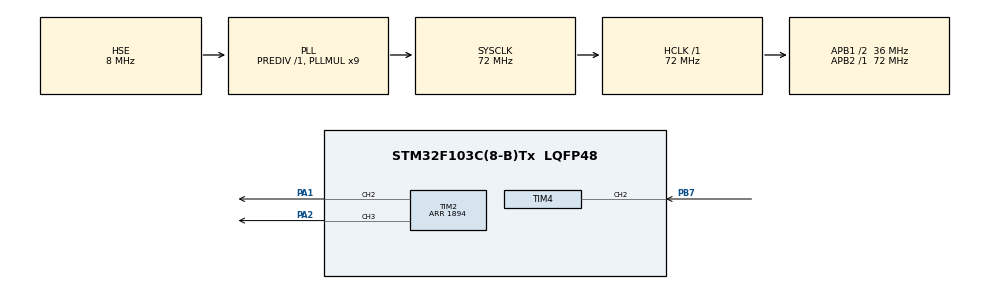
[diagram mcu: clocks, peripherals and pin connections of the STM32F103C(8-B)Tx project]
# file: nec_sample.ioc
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Mcu.Family=STM32F1
Mcu.Name=STM32F103C(8-B)Tx
Mcu.Package=LQFP48
NVIC.PriorityGroup=NVIC_PRIORITYGROUP_4
NVIC.TIM3_IRQn=true\:0\:0\:false\:false\:true\:true\:true\:true
NVIC.TIM4_IRQn=true\:0\:0\:false\:false\:true\:true\:true\:true
PA1.Signal=S_TIM2_CH2
PA13.Mode=Serial_Wire
PA13.Signal=SYS_JTMS-SWDIO
PA14.Mode=Serial_Wire
PA14.Signal=SYS_JTCK-SWCLK
PA2.Signal=S_TIM2_CH3
PB7.Signal=S_TIM4_CH2
PD0-OSC_IN.Mode=HSE-External-Oscillator
PD0-OSC_IN.Signal=RCC_OSC_IN
PD1-OSC_OUT.Mode=HSE-External-Oscillator
PD1-OSC_OUT.Signal=RCC_OSC_OUT
ProjectManager.HeapSize=0x200
ProjectManager.StackSize=0x400
ProjectManager.TargetToolchain=MDK-ARM V5.27
RCC.ADCPresc=RCC_ADCPCLK2_DIV6
RCC.AHBFreq_Value=72000000
RCC.APB1CLKDivider=RCC_HCLK_DIV2
RCC.APB1Freq_Value=36000000
RCC.APB1TimFreq_Value=72000000
RCC.APB2Freq_Value=72000000
RCC.APB2TimFreq_Value=72000000
RCC.HCLKFreq_Value=72000000
RCC.PLLMUL=RCC_PLL_MUL9
RCC.PLLSourceVirtual=RCC_PLLSOURCE_HSE
RCC.SYSCLKFreq_VALUE=72000000
RCC.SYSCLKSource=RCC_SYSCLKSOURCE_PLLCLK
RCC.USBFreq_Value=72000000
SH.S_TIM2_CH2.0=TIM2_CH2,PWM Generation2 CH2
SH.S_TIM2_CH3.0=TIM2_CH3,PWM Generation3 CH3
SH.S_TIM4_CH2.0=TIM4_CH2,Input_Capture2_from_TI2
SH.S_TIM4_CH2.1=TIM4_CH2,TriggerSource_TI2FP2
TIM2.AutoReloadPreload=TIM_AUTORELOAD_PRELOAD_DISABLE
TIM2.Channel-PWM\ Generation2\ CH2=TIM_CHANNEL_2
TIM2.Channel-PWM\ Generation3\ CH3=TIM_CHANNEL_3
TIM2.Period=1894
TIM2.Pulse-PWM\ Generation2\ CH2=625
TIM2.Pulse-PWM\ Generation3\ CH3=625
TIM2.TIM_MasterOutputTrigger=TIM_TRGO_UPDATE
TIM2.TIM_MasterSlaveMode=TIM_MASTERSLAVEMODE_DISABLE
TIM3.Period=0xffff
TIM3.Prescaler=0
TIM3.TIM_MasterOutputTrigger=TIM_TRGO_UPDATE
TIM4.Channel-Input_Capture2_from_TI2=TIM_CHANNEL_2
TIM4.Period=0xffff
TIM4.Prescaler=71
VP_TIM3_VS_ClockSourceITR.Mode=TriggerSource_ITR1
VP_TIM3_VS_ControllerModeClock.Mode=Clock Mode
VP_TIM4_VS_ControllerModeReset.Mode=Reset Mode
board=custom

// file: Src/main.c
/* USER CODE BEGIN Header */
/**
  ******************************************************************************
  * @file           : main.c
  * @brief          : Main program body
  ******************************************************************************
  * @attention
  *
  * Copyright (c) 2025 STMicroelectronics.
  * All rights reserved.
  *
  * This software is licensed under terms that can be found in the LICENSE file
  * in the root directory of this software component.
  * If no LICENSE file comes with this software, it is provided AS-IS.
  *
  ******************************************************************************
  */
/* USER CODE END Header */
#include "main.h"

/* USER CODE BEGIN Includes */
#include "app.h"
/* USER CODE END Includes */

TIM_HandleTypeDef htim2;
TIM_HandleTypeDef htim3;
TIM_HandleTypeDef htim4;

void SystemClock_Config(void);
static void MX_GPIO_Init(void);
static void MX_TIM2_Init(void);
static void MX_TIM4_Init(void);
static void MX_TIM3_Init(void);

int main(void)
{

  /* MCU Configuration--------------------------------------------------------*/

  /* Reset of all peripherals, Initializes the Flash interface and the Systick. */
  HAL_Init();

  /* Configure the system clock */
  SystemClock_Config();

  /* Initialize all configured peripherals */
  MX_GPIO_Init();
  MX_TIM2_Init();
  MX_TIM4_Init();
  MX_TIM3_Init();
  /* USER CODE BEGIN 2 */
  process_init();
  /* USER CODE END 2 */

  /* Infinite loop */
  while (1)
  {

    /* USER CODE BEGIN 3 */
    process();
  }
  /* USER CODE END 3 */
}

void SystemClock_Config(void)
{
  RCC_OscInitTypeDef RCC_OscInitStruct = {0};
  RCC_ClkInitTypeDef RCC_ClkInitStruct = {0};

  /** Initializes the RCC Oscillators according to the specified parameters
  * in the RCC_OscInitTypeDef structure.
  */
  RCC_OscInitStruct.OscillatorType = RCC_OSCILLATORTYPE_HSE;
  RCC_OscInitStruct.HSEState = RCC_HSE_ON;
  RCC_OscInitStruct.HSEPredivValue = RCC_HSE_PREDIV_DIV1;
  RCC_OscInitStruct.HSIState = RCC_HSI_ON;
  RCC_OscInitStruct.PLL.PLLState = RCC_PLL_ON;
  RCC_OscInitStruct.PLL.PLLSource = RCC_PLLSOURCE_HSE;
  RCC_OscInitStruct.PLL.PLLMUL = RCC_PLL_MUL9;
  if (HAL_RCC_OscConfig(&RCC_OscInitStruct) != HAL_OK)
  {
    Error_Handler();
  }

  /** Initializes the CPU, AHB and APB buses clocks
  */
  RCC_ClkInitStruct.ClockType = RCC_CLOCKTYPE_HCLK|RCC_CLOCKTYPE_SYSCLK
                              |RCC_CLOCKTYPE_PCLK1|RCC_CLOCKTYPE_PCLK2;
  RCC_ClkInitStruct.SYSCLKSource = RCC_SYSCLKSOURCE_PLLCLK;
  RCC_ClkInitStruct.AHBCLKDivider = RCC_SYSCLK_DIV1;
  RCC_ClkInitStruct.APB1CLKDivider = RCC_HCLK_DIV2;
  RCC_ClkInitStruct.APB2CLKDivider = RCC_HCLK_DIV1;

  if (HAL_RCC_ClockConfig(&RCC_ClkInitStruct, FLASH_LATENCY_2) != HAL_OK)
  {
    Error_Handler();
  }
}

static void MX_TIM2_Init(void)
{

  TIM_MasterConfigTypeDef sMasterConfig = {0};
  TIM_OC_InitTypeDef sConfigOC = {0};

  htim2.Instance = TIM2;
  htim2.Init.Prescaler = 0;
  htim2.Init.CounterMode = TIM_COUNTERMODE_UP;
  htim2.Init.Period = 1894;
  htim2.Init.ClockDivision = TIM_CLOCKDIVISION_DIV1;
  htim2.Init.AutoReloadPreload = TIM_AUTORELOAD_PRELOAD_DISABLE;
  if (HAL_TIM_PWM_Init(&htim2) != HAL_OK)
  {
    Error_Handler();
  }
  sMasterConfig.MasterOutputTrigger = TIM_TRGO_UPDATE;
  sMasterConfig.MasterSlaveMode = TIM_MASTERSLAVEMODE_DISABLE;
  if (HAL_TIMEx_MasterConfigSynchronization(&htim2, &sMasterConfig) != HAL_OK)
  {
    Error_Handler();
  }
  sConfigOC.OCMode = TIM_OCMODE_PWM1;
  sConfigOC.Pulse = 625;
  sConfigOC.OCPolarity = TIM_OCPOLARITY_HIGH;
  sConfigOC.OCFastMode = TIM_OCFAST_DISABLE;
  if (HAL_TIM_PWM_ConfigChannel(&htim2, &sConfigOC, TIM_CHANNEL_2) != HAL_OK)
  {
    Error_Handler();
  }
  if (HAL_TIM_PWM_ConfigChannel(&htim2, &sConfigOC, TIM_CHANNEL_3) != HAL_OK)
  {
    Error_Handler();
  }
  HAL_TIM_MspPostInit(&htim2);

}

static void MX_TIM3_Init(void)
{

  TIM_SlaveConfigTypeDef sSlaveConfig = {0};
  TIM_MasterConfigTypeDef sMasterConfig = {0};

  htim3.Instance = TIM3;
  htim3.Init.Prescaler = 0;
  htim3.Init.CounterMode = TIM_COUNTERMODE_UP;
  htim3.Init.Period = 0xffff;
  htim3.Init.ClockDivision = TIM_CLOCKDIVISION_DIV1;
  htim3.Init.AutoReloadPreload = TIM_AUTORELOAD_PRELOAD_DISABLE;
  if (HAL_TIM_Base_Init(&htim3) != HAL_OK)
  {
    Error_Handler();
  }
  sSlaveConfig.SlaveMode = TIM_SLAVEMODE_EXTERNAL1;
  sSlaveConfig.InputTrigger = TIM_TS_ITR1;
  if (HAL_TIM_SlaveConfigSynchro(&htim3, &sSlaveConfig) != HAL_OK)
  {
    Error_Handler();
  }
  sMasterConfig.MasterOutputTrigger = TIM_TRGO_UPDATE;
  sMasterConfig.MasterSlaveMode = TIM_MASTERSLAVEMODE_DISABLE;
  if (HAL_TIMEx_MasterConfigSynchronization(&htim3, &sMasterConfig) != HAL_OK)
  {
    Error_Handler();
  }

}

static void MX_TIM4_Init(void)
{

  TIM_SlaveConfigTypeDef sSlaveConfig = {0};
  TIM_MasterConfigTypeDef sMasterConfig = {0};
  TIM_IC_InitTypeDef sConfigIC = {0};

  htim4.Instance = TIM4;
  htim4.Init.Prescaler = 71;
  htim4.Init.CounterMode = TIM_COUNTERMODE_UP;
  htim4.Init.Period = 0xffff;
  htim4.Init.ClockDivision = TIM_CLOCKDIVISION_DIV1;
  htim4.Init.AutoReloadPreload = TIM_AUTORELOAD_PRELOAD_DISABLE;
  if (HAL_TIM_Base_Init(&htim4) != HAL_OK)
  {
    Error_Handler();
  }
  if (HAL_TIM_IC_Init(&htim4) != HAL_OK)
  {
    Error_Handler();
  }
  sSlaveConfig.SlaveMode = TIM_SLAVEMODE_RESET;
  sSlaveConfig.InputTrigger = TIM_TS_TI2FP2;
  sSlaveConfig.TriggerPolarity = TIM_INPUTCHANNELPOLARITY_RISING;
  sSlaveConfig.TriggerFilter = 0;
  if (HAL_TIM_SlaveConfigSynchro(&htim4, &sSlaveConfig) != HAL_OK)
  {
    Error_Handler();
  }
  sMasterConfig.MasterOutputTrigger = TIM_TRGO_RESET;
  sMasterConfig.MasterSlaveMode = TIM_MASTERSLAVEMODE_DISABLE;
  if (HAL_TIMEx_MasterConfigSynchronization(&htim4, &sMasterConfig) != HAL_OK)
  {
    Error_Handler();
  }
  sConfigIC.ICPolarity = TIM_INPUTCHANNELPOLARITY_RISING;
  sConfigIC.ICSelection = TIM_ICSELECTION_DIRECTTI;
  sConfigIC.ICPrescaler = TIM_ICPSC_DIV1;
  sConfigIC.ICFilter = 0;
  if (HAL_TIM_IC_ConfigChannel(&htim4, &sConfigIC, TIM_CHANNEL_2) != HAL_OK)
  {
    Error_Handler();
  }

}

static void MX_GPIO_Init(void)
{
  GPIO_InitTypeDef GPIO_InitStruct = {0};

  /* GPIO Ports Clock Enable */
  __HAL_RCC_GPIOC_CLK_ENABLE();
  __HAL_RCC_GPIOD_CLK_ENABLE();
  __HAL_RCC_GPIOA_CLK_ENABLE();
  __HAL_RCC_GPIOB_CLK_ENABLE();

  /*Configure GPIO pins : PC13 PC14 PC15 */
  GPIO_InitStruct.Pin = GPIO_PIN_13|GPIO_PIN_14|GPIO_PIN_15;
  GPIO_InitStruct.Mode = GPIO_MODE_ANALOG;
  HAL_GPIO_Init(GPIOC, &GPIO_InitStruct);

  /*Configure GPIO pins : PA0 PA3 PA4 PA5
                           PA6 PA7 PA8 PA9
                           PA10 PA11 PA12 PA15 */
  GPIO_InitStruct.Pin = GPIO_PIN_0|GPIO_PIN_3|GPIO_PIN_4|GPIO_PIN_5
                          |GPIO_PIN_6|GPIO_PIN_7|GPIO_PIN_8|GPIO_PIN_9
                          |GPIO_PIN_10|GPIO_PIN_11|GPIO_PIN_12|GPIO_PIN_15;
  GPIO_InitStruct.Mode = GPIO_MODE_ANALOG;
  HAL_GPIO_Init(GPIOA, &GPIO_InitStruct);

  /*Configure GPIO pins : PB0 PB1 PB2 PB10
                           PB11 PB12 PB13 PB14
                           PB15 PB3 PB4 PB5
                           PB6 PB8 PB9 */
  GPIO_InitStruct.Pin = GPIO_PIN_0|GPIO_PIN_1|GPIO_PIN_2|GPIO_PIN_10
                          |GPIO_PIN_11|GPIO_PIN_12|GPIO_PIN_13|GPIO_PIN_14
                          |GPIO_PIN_15|GPIO_PIN_3|GPIO_PIN_4|GPIO_PIN_5
                          |GPIO_PIN_6|GPIO_PIN_8|GPIO_PIN_9;
  GPIO_InitStruct.Mode = GPIO_MODE_ANALOG;
  HAL_GPIO_Init(GPIOB, &GPIO_InitStruct);

}

void Error_Handler(void)
{
  __disable_irq();
  while (1)
  {
  }
}
